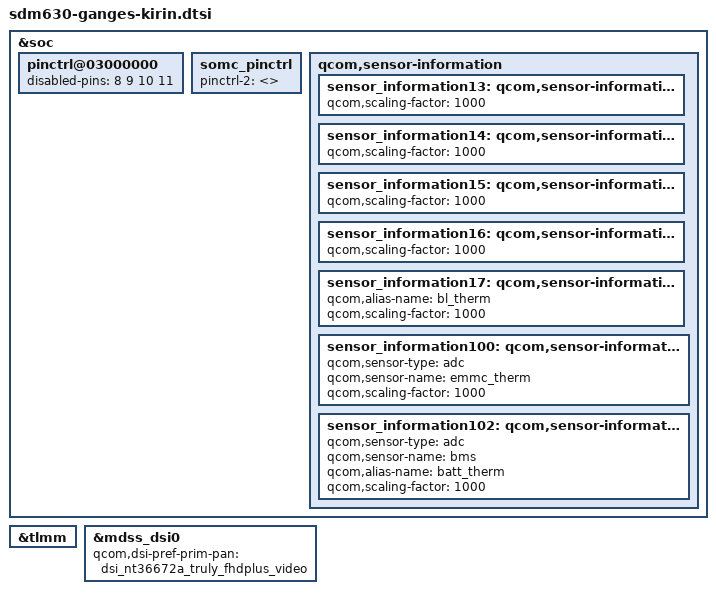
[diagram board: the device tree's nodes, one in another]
/* arch/arm64/boot/dts/somc/sdm630-ganges-kirin.dtsi
 *
 * This program is free software; you can redistribute it and/or modify
 * it under the terms of the GNU General Public License version 2 and
 * only version 2 as published by the Free Software Foundation.
 *
 * This program is distributed in the hope that it will be useful,
 * but WITHOUT ANY WARRANTY; without even the implied warranty of
 * MERCHANTABILITY or FITNESS FOR A PARTICULAR PURPOSE.  See the
 * GNU General Public License for more details.
*/

#include "sdm630-ganges-common.dtsi"
#include "dsi-panel-somc-kirin.dtsi"
#include "sdm630-ganges-kirin-touch.dtsi"
#include "sdm630-ganges-kirin-camera-sensor.dtsi"
#include "sdm630-ganges-kirin-common.dtsi"

&soc {
	pinctrl@03000000 {
		disabled-pins = <8 9 10 11>;
	};

	somc_pinctrl: somc_pinctrl {
		/* If variant specific default setting is needed,
		fill pinctrl-2 value in <variant>.dtsi */
		pinctrl-2 = <>;
	};

	qcom,sensor-information {
		sensor_information13: qcom,sensor-information-13 { /* msm_therm */
			qcom,scaling-factor = <1000>;
		};
		sensor_information14: qcom,sensor-information-14 { /* xo_therm */
			qcom,scaling-factor = <1000>;
		};
		sensor_information15: qcom,sensor-information-15 { /* pa_therm0 */
			qcom,scaling-factor = <1000>;
		};
		sensor_information16: qcom,sensor-information-16 { /* pa_therm1 */
			qcom,scaling-factor = <1000>;
		};
		sensor_information17: qcom,sensor-information-17 { /* quiet_therm */
			qcom,alias-name = "bl_therm";
			qcom,scaling-factor = <1000>;
		};
		sensor_information100: qcom,sensor-information-100 { /* emmc_therm */
			qcom,sensor-type = "adc";
			qcom,sensor-name = "emmc_therm";
			qcom,scaling-factor = <1000>;
		};
		sensor_information102: qcom,sensor-information-101 { /* bms */
			qcom,sensor-type = "adc";
			qcom,sensor-name = "bms";
			qcom,alias-name = "batt_therm";
			qcom,scaling-factor = <1000>;
		};
	};

};

&tlmm {
};

&mdss_dsi0 {
	qcom,dsi-pref-prim-pan = <&dsi_nt36672a_truly_fhdplus_video>;
};
